AUTOSAR XML (schema 4-0-3)
standard types defined: Boolean, uint8, UInt16, UInt32, UInt8
package /AUTOSAR_Platform/DataConstrs
  range DC_Boolean: raw 0..1
  range DC_UInt16: raw 0..65535
  range DC_UInt8: raw 0..255
package /PATAC/Facility/DataTypes/Implementation
  compu method COMPU_Boolean: 0=FALSE, 1=TRUE
  unit NoUnit: factor-si-to-unit=1, offset-si-to-unit=0
package /PATAC/MSM/ComponentTypes
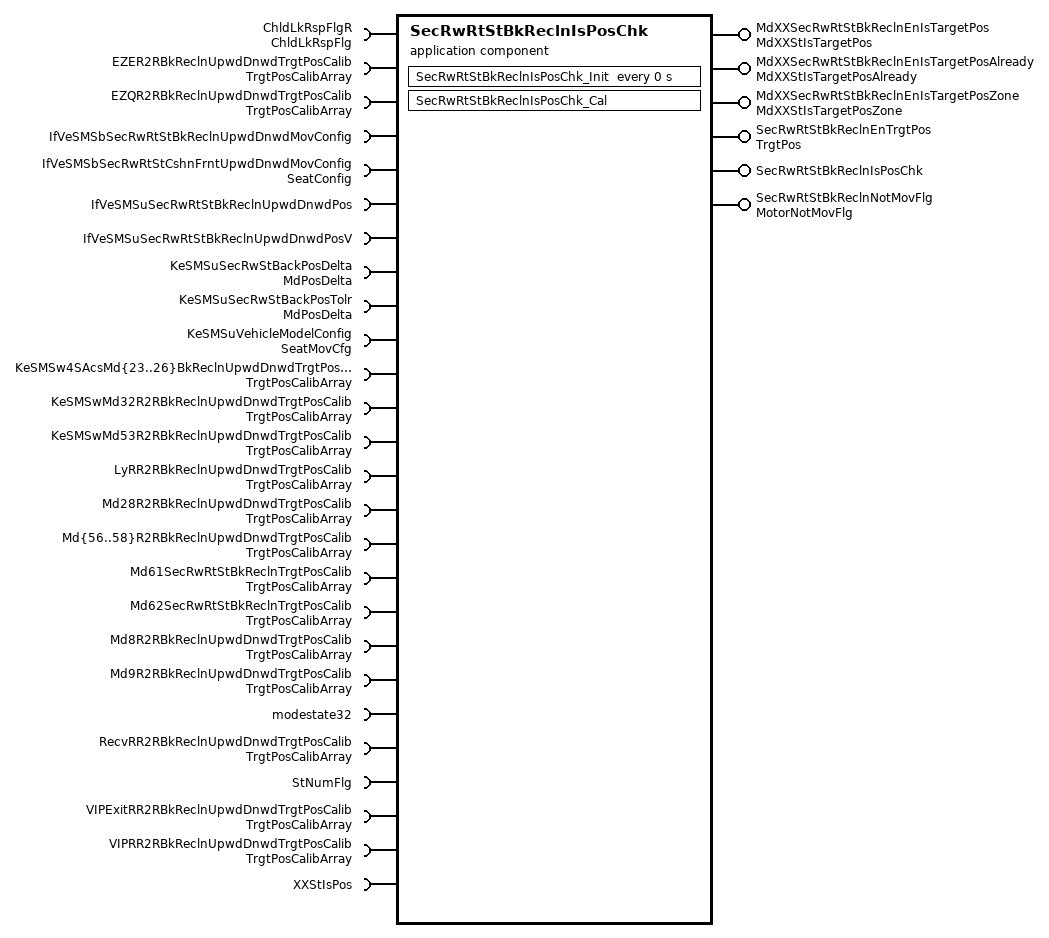
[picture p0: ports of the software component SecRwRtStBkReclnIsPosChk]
  application sw component type SecRwRtStBkReclnIsPosChk
    6 x provide port:
      MdXXSecRwRtStBkReclnEnIsTargetPos: nonqueued-sender-com-spec=data-element=MdXXStIsTargetPos/Val, provided-interface=MdXXStIsTargetPos
      MdXXSecRwRtStBkReclnEnIsTargetPosAlready: nonqueued-sender-com-spec=data-element=MdXXStIsTargetPosAlready/Val, provided-interface=MdXXStIsTargetPosAlready
      MdXXSecRwRtStBkReclnEnIsTargetPosZone: nonqueued-sender-com-spec=data-element=MdXXStIsTargetPosZone/Val, provided-interface=MdXXStIsTargetPosZone
      SecRwRtStBkReclnEnTrgtPos: nonqueued-sender-com-spec{data-element=TrgtPos/Val, init-value=4095}, provided-interface=TrgtPos
      SecRwRtStBkReclnIsPosChk: server-com-spec{operation=Cal, queue-length=1}, provided-interface=SecRwRtStBkReclnIsPosChk
      SecRwRtStBkReclnNotMovFlg: nonqueued-sender-com-spec{data-element=MotorNotMovFlg/Val, init-value=0}, provided-interface=MotorNotMovFlg
    31 x require port:
      ChldLkRspFlgR: nonqueued-receiver-com-spec{data-element=ChldLkRspFlg/Val, filter=data-filter-type=ALWAYS, init-value=0}, required-interface=ChldLkRspFlg
      EZER2RBkReclnUpwdDnwdTrgtPosCalib: nonqueued-receiver-com-spec{data-element=TrgtPosArray, filter=data-filter-type=ALWAYS, init-value=[4095, 4095, 4095]}, required-interface=TrgtPosCalibArray
      EZQR2RBkReclnUpwdDnwdTrgtPosCalib: nonqueued-receiver-com-spec{data-element=TrgtPosArray, filter=data-filter-type=ALWAYS, init-value=[4095, 4095, 4095]}, required-interface=TrgtPosCalibArray
      IfVeSMSbSecRwRtStBkReclnUpwdDnwdMovConfig: nonqueued-receiver-com-spec{data-element=IfVeSMSbSecRwRtStBkReclnUpwdDnwdMovConfig/Val, filter=data-filter-type=ALWAYS, init-value=0}, required-interface=IfVeSMSbSecRwRtStBkReclnUpwdDnwdMovConfig
      IfVeSMSbSecRwRtStCshnFrntUpwdDnwdMovConfig: nonqueued-receiver-com-spec{data-element=SeatConfig/Val, filter=data-filter-type=ALWAYS, init-value=0}, required-interface=SeatConfig
      IfVeSMSuSecRwRtStBkReclnUpwdDnwdPos: nonqueued-receiver-com-spec{data-element=IfVeSMSuSecRwRtStBkReclnUpwdDnwdPos/Val, filter=data-filter-type=ALWAYS, init-value=0}, required-interface=IfVeSMSuSecRwRtStBkReclnUpwdDnwdPos
      IfVeSMSuSecRwRtStBkReclnUpwdDnwdPosV: nonqueued-receiver-com-spec{data-element=IfVeSMSuSecRwRtStBkReclnUpwdDnwdPosV/Val, filter=data-filter-type=ALWAYS, init-value=0}, required-interface=IfVeSMSuSecRwRtStBkReclnUpwdDnwdPosV
      KeSMSuSecRwStBackPosDelta: parameter-require-com-spec{init-value=150, parameter=MdPosDelta/Val}, required-interface=MdPosDelta
      KeSMSuSecRwStBackPosTolr: parameter-require-com-spec{init-value=150, parameter=MdPosDelta/Val}, required-interface=MdPosDelta
      KeSMSuVehicleModelConfig: parameter-require-com-spec{init-value=2, parameter=SeatMovCfg/Val}, required-interface=SeatMovCfg
      KeSMSw4SAcsMd{23..26}BkReclnUpwdDnwdTrgtPosCalib: nonqueued-receiver-com-spec{data-element=TrgtPosArray, filter=data-filter-type=ALWAYS, init-value=[4095, 4095, 4095]}, required-interface=TrgtPosCalibArray
      KeSMSwMd32R2RBkReclnUpwdDnwdTrgtPosCalib: nonqueued-receiver-com-spec{data-element=TrgtPosArray, filter=data-filter-type=ALWAYS, init-value=[4095, 4095, 4095]}, required-interface=TrgtPosCalibArray
      KeSMSwMd53R2RBkReclnUpwdDnwdTrgtPosCalib: nonqueued-receiver-com-spec{data-element=TrgtPosArray, filter=data-filter-type=ALWAYS, init-value=[4095, 4095, 4095]}, required-interface=TrgtPosCalibArray
      LyRR2RBkReclnUpwdDnwdTrgtPosCalib: nonqueued-receiver-com-spec{data-element=TrgtPosArray, filter=data-filter-type=ALWAYS, init-value=[4095, 4095, 4095]}, required-interface=TrgtPosCalibArray
      Md28R2RBkReclnUpwdDnwdTrgtPosCalib: nonqueued-receiver-com-spec{data-element=TrgtPosArray, filter=data-filter-type=ALWAYS, init-value=[4095, 4095, 4095]}, required-interface=TrgtPosCalibArray
      Md{56..58}R2RBkReclnUpwdDnwdTrgtPosCalib: nonqueued-receiver-com-spec{data-element=TrgtPosArray, filter=data-filter-type=ALWAYS, init-value=[4095, 4095, 4095]}, required-interface=TrgtPosCalibArray
      Md61SecRwRtStBkReclnTrgtPosCalib: nonqueued-receiver-com-spec{data-element=TrgtPosArray, filter=data-filter-type=ALWAYS, init-value=[4095, 4095, 4095]}, required-interface=TrgtPosCalibArray
      Md62SecRwRtStBkReclnTrgtPosCalib: nonqueued-receiver-com-spec{data-element=TrgtPosArray, filter=data-filter-type=ALWAYS, init-value=[4095, 4095, 4095]}, required-interface=TrgtPosCalibArray
      Md8R2RBkReclnUpwdDnwdTrgtPosCalib: nonqueued-receiver-com-spec{data-element=TrgtPosArray, filter=data-filter-type=ALWAYS, init-value=[4095, 4095, 4095]}, required-interface=TrgtPosCalibArray
      Md9R2RBkReclnUpwdDnwdTrgtPosCalib: nonqueued-receiver-com-spec{data-element=TrgtPosArray, filter=data-filter-type=ALWAYS, init-value=[4095, 4095, 4095]}, required-interface=TrgtPosCalibArray
      modestate32: nonqueued-receiver-com-spec{data-element=modestate32/Val, filter=data-filter-type=ALWAYS, init-value=0}, required-interface=modestate32
      RecvRR2RBkReclnUpwdDnwdTrgtPosCalib: nonqueued-receiver-com-spec{data-element=TrgtPosArray, filter=data-filter-type=ALWAYS, init-value=[4095, 4095, 4095]}, required-interface=TrgtPosCalibArray
      StNumFlg: required-interface=StNumFlg
        required-com-specs:
          data-element=Is4s, filter=data-filter-type=ALWAYS, init-value=0
          data-element=Is6s, filter=data-filter-type=ALWAYS, init-value=0
          data-element=Is6s7s, filter=data-filter-type=ALWAYS, init-value=0
          data-element=Is7s, filter=data-filter-type=ALWAYS, init-value=0
      VIPExitRR2RBkReclnUpwdDnwdTrgtPosCalib: nonqueued-receiver-com-spec{data-element=TrgtPosArray, filter=data-filter-type=ALWAYS, init-value=[4095, 4095, 4095]}, required-interface=TrgtPosCalibArray
      VIPRR2RBkReclnUpwdDnwdTrgtPosCalib: nonqueued-receiver-com-spec{data-element=TrgtPosArray, filter=data-filter-type=ALWAYS, init-value=[4095, 4095, 4095]}, required-interface=TrgtPosCalibArray
      XXStIsPos: client-com-spec=Get, required-interface=XXStIsPos
    behavior SecRwRtStBkReclnIsPosChk_InternalBehavior
      operation invoked event OIT_SecRwRtStBkReclnIsPosChk_Cal_SecRwRtStBkReclnIsPosChk_Cal: start-on-event=SecRwRtStBkReclnIsPosChk_Cal, operation=SecRwRtStBkReclnIsPosChk.Cal
      timing event SecRwRtStBkReclnIsPosChk_InitEvent: start-on-event=SecRwRtStBkReclnIsPosChk_Init, period=0
      runnable SecRwRtStBkReclnIsPosChk_Cal
        data-receive-point-by-arguments:
          30 x access:
            REC_ChldLkRspFlgR_Val: accessed-variable=ChldLkRspFlgR.Val
            REC_EZER2RBkReclnUpwdDnwdTrgtPosCalib_TrgtPosArray: accessed-variable=EZER2RBkReclnUpwdDnwdTrgtPosCalib.TrgtPosArray
            REC_EZQR2RBkReclnUpwdDnwdTrgtPosCalib_TrgtPosArray: accessed-variable=EZQR2RBkReclnUpwdDnwdTrgtPosCalib.TrgtPosArray
            REC_IfVeSMSbSecRwRtStBkReclnUpwdDnwdMovConfig_Val: accessed-variable=IfVeSMSbSecRwRtStBkReclnUpwdDnwdMovConfig.Val
            REC_IfVeSMSbSecRwRtStCshnFrntUpwdDnwdMovConfig_Val: accessed-variable=IfVeSMSbSecRwRtStCshnFrntUpwdDnwdMovConfig.Val
            REC_IfVeSMSuSecRwRtStBkReclnUpwdDnwdPos_Val: accessed-variable=IfVeSMSuSecRwRtStBkReclnUpwdDnwdPos.Val
            REC_IfVeSMSuSecRwRtStBkReclnUpwdDnwdPosV_Val: accessed-variable=IfVeSMSuSecRwRtStBkReclnUpwdDnwdPosV.Val
            REC_KeSMSw4SAcsMd{23..26}BkReclnUpwdDnwdTrgtPosCalib_TrgtPosArray: accessed-variable=KeSMSw4SAcsMd{23..26}BkReclnUpwdDnwdTrgtPosCalib.TrgtPosArray
            REC_KeSMSwMd32R2RBkReclnUpwdDnwdTrgtPosCalib_TrgtPosArray: accessed-variable=KeSMSwMd32R2RBkReclnUpwdDnwdTrgtPosCalib.TrgtPosArray
            REC_KeSMSwMd53R2RBkReclnUpwdDnwdTrgtPosCalib_TrgtPosArray: accessed-variable=KeSMSwMd53R2RBkReclnUpwdDnwdTrgtPosCalib.TrgtPosArray
            REC_LyRR2RBkReclnUpwdDnwdTrgtPosCalib_TrgtPosArray: accessed-variable=LyRR2RBkReclnUpwdDnwdTrgtPosCalib.TrgtPosArray
            REC_Md28R2RBkReclnUpwdDnwdTrgtPosCalib_TrgtPosArray: accessed-variable=Md28R2RBkReclnUpwdDnwdTrgtPosCalib.TrgtPosArray
            REC_Md{56..58}R2RBkReclnUpwdDnwdTrgtPosCalib_TrgtPosArray: accessed-variable=Md{56..58}R2RBkReclnUpwdDnwdTrgtPosCalib.TrgtPosArray
            REC_Md61SecRwRtStBkReclnTrgtPosCalib_TrgtPosArray: accessed-variable=Md61SecRwRtStBkReclnTrgtPosCalib.TrgtPosArray
            REC_Md62SecRwRtStBkReclnTrgtPosCalib_TrgtPosArray: accessed-variable=Md62SecRwRtStBkReclnTrgtPosCalib.TrgtPosArray
            REC_Md8R2RBkReclnUpwdDnwdTrgtPosCalib_TrgtPosArray: accessed-variable=Md8R2RBkReclnUpwdDnwdTrgtPosCalib.TrgtPosArray
            REC_Md9R2RBkReclnUpwdDnwdTrgtPosCalib_TrgtPosArray: accessed-variable=Md9R2RBkReclnUpwdDnwdTrgtPosCalib.TrgtPosArray
            REC_modestate32_Val: accessed-variable=modestate32.Val
            REC_RecvRR2RBkReclnUpwdDnwdTrgtPosCalib_TrgtPosArray: accessed-variable=RecvRR2RBkReclnUpwdDnwdTrgtPosCalib.TrgtPosArray
            REC_StNumFlg_Is4s: accessed-variable=StNumFlg.Is4s
            REC_StNumFlg_Is6s: accessed-variable=StNumFlg.Is6s
            REC_StNumFlg_Is6s7s: accessed-variable=StNumFlg.Is6s7s
            REC_StNumFlg_Is7s: accessed-variable=StNumFlg.Is7s
            REC_VIPExitRR2RBkReclnUpwdDnwdTrgtPosCalib_TrgtPosArray: accessed-variable=VIPExitRR2RBkReclnUpwdDnwdTrgtPosCalib.TrgtPosArray
            REC_VIPRR2RBkReclnUpwdDnwdTrgtPosCalib_TrgtPosArray: accessed-variable=VIPRR2RBkReclnUpwdDnwdTrgtPosCalib.TrgtPosArray
        data-send-points:
          5 x access:
            SEND_MdXXSecRwRtStBkReclnEnIsTargetPos_Val: accessed-variable=MdXXSecRwRtStBkReclnEnIsTargetPos.Val
            SEND_MdXXSecRwRtStBkReclnEnIsTargetPosAlready_Val: accessed-variable=MdXXSecRwRtStBkReclnEnIsTargetPosAlready.Val
            SEND_MdXXSecRwRtStBkReclnEnIsTargetPosZone_Val: accessed-variable=MdXXSecRwRtStBkReclnEnIsTargetPosZone.Val
            SEND_SecRwRtStBkReclnEnTrgtPos_Val: accessed-variable=SecRwRtStBkReclnEnTrgtPos.Val
            SEND_SecRwRtStBkReclnNotMovFlg_Val: accessed-variable=SecRwRtStBkReclnNotMovFlg.Val
        parameter access PA_KeSMSuSecRwStBackPosDelta_Val: accessed-parameter=KeSMSuSecRwStBackPosDelta.Val
        parameter access PA_KeSMSuSecRwStBackPosTolr_Val: accessed-parameter=KeSMSuSecRwStBackPosTolr.Val
        parameter access PA_KeSMSuVehicleModelConfig_Val: accessed-parameter=KeSMSuVehicleModelConfig.Val
        sync call SC_XXStIsPos_Get: operation=XXStIsPos.Get, timeout=0
      runnable SecRwRtStBkReclnIsPosChk_Init
        parameter access PA_KeSMSuSecRwStBackPosDelta_Val: accessed-parameter=KeSMSuSecRwStBackPosDelta.Val
        parameter access PA_KeSMSuSecRwStBackPosTolr_Val: accessed-parameter=KeSMSuSecRwStBackPosTolr.Val
        parameter access PA_KeSMSuVehicleModelConfig_Val: accessed-parameter=KeSMSuVehicleModelConfig.Val
  swc implementation SecRwRtStBkReclnIsPosChk_Implementation: behavior=SecRwRtStBkReclnIsPosChk_InternalBehavior
    code-descriptors:
      code Default: artifact-descriptors=autosar-engineering-object={short-label=Default, category=SWSRC}
package /PATAC/MSM/DataTypes
  parameter interface SeatMovCfg
    parameter data prototype Val: sw-calibration-access=READ-WRITE, type=UInt8
package /PATAC/MSM/ModeAdjust/CalPortInterface
  parameter interface MdPosDelta
    parameter data prototype Val: sw-calibration-access=READ-WRITE, type=UInt16
package /PATAC/MSM/ModeAdjust/DataType
  impl type TrgtPosCalibArray: category=ARRAY, sw-calibration-access=READ-ONLY, type-emitter=RTE  # 0:pos 1:max 2:min
    element Element: array-size=3, array-size-semantics=FIXED-SIZE, implementation-data-type=UInt16, invalid-value=0
package /PATAC/MSM/ModeAdjust/Interfaces
  sender receiver interface IfVeSMSuSecRwRtStBkReclnUpwdDnwdPosV: invalidation-policy{data-element=IfVeSMSuSecRwRtStBkReclnUpwdDnwdPosV/Val, handle-invalid=DONT-INVALIDATE}
    data Val: type=Implementation/Boolean
package /PATAC/MSM/ModeAdjust/PortInterface
  client server interface SecRwRtStBkReclnIsPosChk
    operation Cal
  client server interface XXStIsPos
    operation Get
      8 x arg, all with server-argument-impl-policy=USE-ARGUMENT-TYPE:
        PosV: type=DataTypes/Boolean, direction=IN
        Pos: type=UInt16, direction=IN
        CalibArray: type=TrgtPosCalibArray, direction=IN
        Delta: type=UInt16, direction=IN
        Tolr: type=UInt16, direction=IN
        IsPos: type=DataTypes/Boolean, direction=OUT
        IsPosZone: type=DataTypes/Boolean, direction=OUT
        IsPosAlready: type=DataTypes/Boolean, direction=OUT
  8 x sender receiver interface:
    ChldLkRspFlg: invalidation-policy{data-element=ChldLkRspFlg/Val, handle-invalid=DONT-INVALIDATE}
      data Val: type=Implementation/Boolean
    MdXXStIsTargetPos: invalidation-policy{data-element=MdXXStIsTargetPos/Val, handle-invalid=DONT-INVALIDATE}
      data Val: type=UInt32
    MdXXStIsTargetPosAlready: invalidation-policy{data-element=MdXXStIsTargetPosAlready/Val, handle-invalid=DONT-INVALIDATE}
      data Val: type=UInt32
    MdXXStIsTargetPosZone: invalidation-policy{data-element=MdXXStIsTargetPosZone/Val, handle-invalid=DONT-INVALIDATE}
      data Val: type=UInt32
    modestate32: invalidation-policy{data-element=modestate32/Val, handle-invalid=DONT-INVALIDATE}
      data Val: type=UInt32
    MotorNotMovFlg: invalidation-policy{data-element=MotorNotMovFlg/Val, handle-invalid=DONT-INVALIDATE}
      data Val: type=Implementation/Boolean
    StNumFlg
      4 x data, all with type=Implementation/Boolean:
        Is4s
        Is6s
        Is6s7s
        Is7s
      invalidation-policys:
        data-element=Is4s, handle-invalid=DONT-INVALIDATE
        data-element=Is6s, handle-invalid=DONT-INVALIDATE
        data-element=Is6s7s, handle-invalid=DONT-INVALIDATE
        data-element=Is7s, handle-invalid=DONT-INVALIDATE
    TrgtPosCalibArray: invalidation-policy{data-element=TrgtPosArray, handle-invalid=DONT-INVALIDATE}
      data TrgtPosArray: type=TrgtPosCalibArray  # 0:Pos 1:Max 2:Min
package /PATAC/MSM/PortInterfaces
  4 x sender receiver interface:
    IfVeSMSbSecRwRtStBkReclnUpwdDnwdMovConfig: invalidation-policy{data-element=IfVeSMSbSecRwRtStBkReclnUpwdDnwdMovConfig/Val, handle-invalid=DONT-INVALIDATE}
      data Val: type=Implementation/Boolean
    IfVeSMSuSecRwRtStBkReclnUpwdDnwdPos: invalidation-policy{data-element=IfVeSMSuSecRwRtStBkReclnUpwdDnwdPos/Val, handle-invalid=DONT-INVALIDATE}
      data Val: type=UInt16
    SeatConfig: invalidation-policy{data-element=SeatConfig/Val, handle-invalid=DONT-INVALIDATE}
      data Val: type=Implementation/Boolean
    TrgtPos: invalidation-policy{data-element=TrgtPos/Val, handle-invalid=DONT-INVALIDATE}
      data Val: type=UInt16
